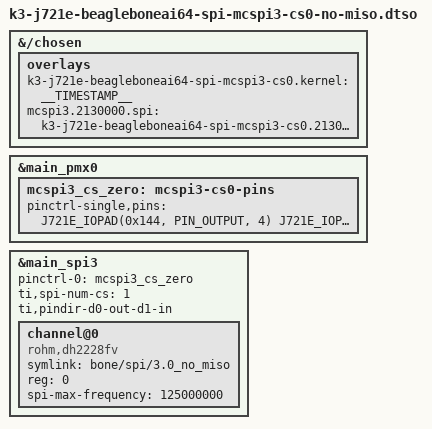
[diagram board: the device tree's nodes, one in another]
// SPDX-License-Identifier: GPL-2.0-only OR MIT
/*
 * DT Overlay for SPI6 pins P8_40(cs0), P8_46(clk), P9_40b(MOSI).
 *
 * Copyright (C) 2023 Texas Instruments Incorporated - https://www.ti.com/
 *
 */

/dts-v1/;
/plugin/;

#include <dt-bindings/gpio/gpio.h>
#include "k3-pinctrl.h"

/*
 * Helper to show loaded overlays under: /proc/device-tree/chosen/overlays/
*/
&{/chosen} {
        overlays {
                k3-j721e-beagleboneai64-spi-mcspi3-cs0.kernel = __TIMESTAMP__;
                mcspi3.2130000.spi = "k3-j721e-beagleboneai64-spi-mcspi3-cs0.2130000";
        };
};

/* To figure out which SoC pad numbers go with which BB header pins, look at columns A and B
 * in the following spreadsheet. To figure out mux modes, look at row 10.
 * https://drive.google.com/file/d/15NLaUeMBy-iT8s6rFrP4Esf0Qh57T4xu/view?pli=1
 *
 * To figure out the addresses of SoC pads, look at table "Table 5-125. Pin Multiplexing" in the TDA4VM Processor datasheet
 * https://www.ti.com/lit/ds/symlink/tda4vm.pdf?ts=1741890214437&ref_url=https%253A%252F%252Fwww.ti.com%252Fproduct%252FTDA4VM
 *
*/
&main_pmx0 {
    mcspi3_cs_zero: mcspi3-cs0-pins {
        pinctrl-single,pins = <
            /* Used TI SysConfig app to generate these, had manually adjust output modes */
            J721E_IOPAD(0x144, PIN_OUTPUT, 4) /* (Y25) PRG0_PRU1_GPO17.SPI3_CLK P8_46 */
            J721E_IOPAD(0x11c, PIN_OUTPUT, 4) /* (AA24) PRG0_PRU1_GPO7.SPI3_CS0 P8_40*/
            J721E_IOPAD(0x148, PIN_OUTPUT, 4) /* (AA26) PRG0_PRU1_GPO18.SPI3_D0 P9_40b*/

            /* Disable SoC pins that share same BB header pins
             *
             * Turns out there is no P9_40a pin connected to the main domain. You may be tempted to disable the pad K26
             * using the J721E_WKUP_IOPAD() macro. It turns out in actuality this disables P8_20. MCU pad K26 and main domain
             * pad AF2,as seen from the processor datasheet, happen to have the same address 11c134. It turns out the
             * J721E_IOPAD() and J721E_WKUP_IOPAD() marcos are the same. They do not do anything different.
             *
            */
        >;
    };
};

/*
 * Most of the stuff in this section is here for the spidev linux driver. For control from
 * from a DSP or R5 core, only the status and pinctrl parts matter.
 *
 * Make sure to load the spidev driver to control SPI from linux.
 */
&main_spi3 {
    #address-cells = <1>;
    #size-cells = <0>;
    pinctrl-names = "default";
    pinctrl-0 = <&mcspi3_cs_zero>;
    ti,spi-num-cs = <1>; /* With this number wrong, no spi device would get created, error seen with `sudo journalctl -k` */
    ti,pindir-d0-out-d1-in; /* d1 is not really an input, the pin is not muxed */
    status = "okay";

    /* When controlling SPI from outside linux, you may want to delete this spidev stuff */
    channel@0 {
        symlink = "bone/spi/3.0_no_miso"; /* /dev/bone/spi/3.0_no_miso */
        compatible = "rohm,dh2228fv";
        reg = <0>; /* CE0 */
        spi-max-frequency = <125000000>;
    };
};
